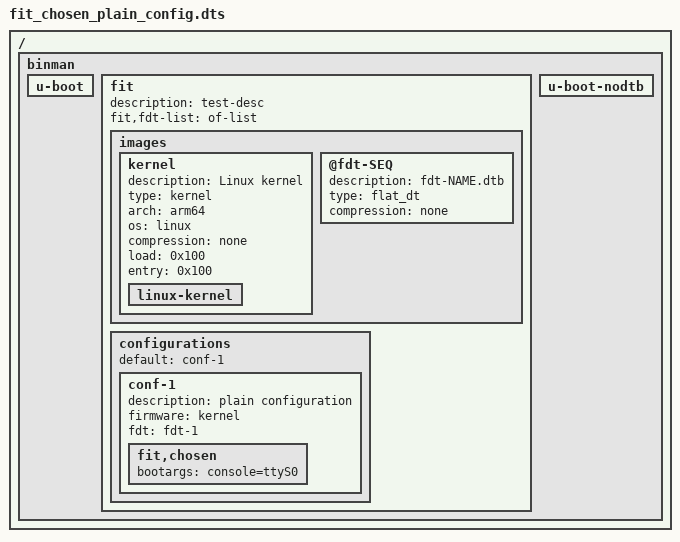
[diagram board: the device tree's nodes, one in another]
// SPDX-License-Identifier: GPL-2.0+
// SPDX-FileCopyrightText: 2026 Flipper FZCO

/dts-v1/;

/ {
	#address-cells = <1>;
	#size-cells = <1>;

	binman {
		u-boot {
		};
		fit {
			description = "test-desc";
			#address-cells = <1>;
			fit,fdt-list = "of-list";

			images {
				kernel {
					description = "Linux kernel";
					type = "kernel";
					arch = "arm64";
					os = "linux";
					compression = "none";
					load = <0x100>;
					entry = <0x100>;
					linux-kernel {
					};
				};
				@fdt-SEQ {
					description = "fdt-NAME.dtb";
					type = "flat_dt";
					compression = "none";
				};
			};

			configurations {
				default = "conf-1";
				conf-1 {
					description = "plain configuration";
					firmware = "kernel";
					fdt = "fdt-1";

					/* Only valid in the images generator node */
					fit,chosen {
						bootargs = "console=ttyS0";
					};
				};
			};
		};
		u-boot-nodtb {
		};
	};
};
